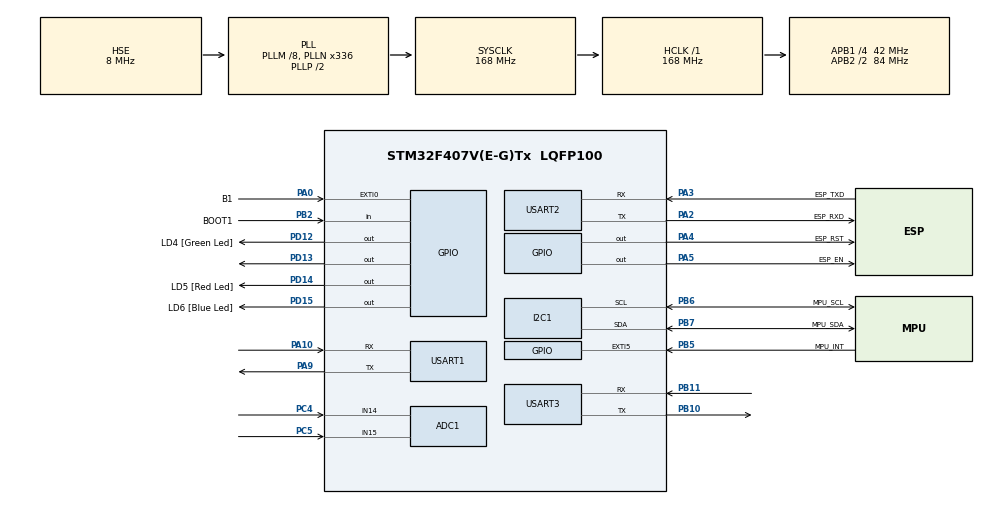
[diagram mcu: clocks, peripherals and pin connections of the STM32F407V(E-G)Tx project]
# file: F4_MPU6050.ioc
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ADC1.Channel-4\#ChannelRegularConversion=ADC_CHANNEL_14
ADC1.Channel-5\#ChannelRegularConversion=ADC_CHANNEL_15
ADC1.DMAContinuousRequests=ENABLE
ADC1.EOCSelection=ADC_EOC_SEQ_CONV
ADC1.ExternalTrigConv=ADC_EXTERNALTRIGCONV_T3_TRGO
ADC1.NbrOfConversion=2
ADC1.NbrOfConversionFlag=1
ADC1.Rank-4\#ChannelRegularConversion=1
ADC1.Rank-5\#ChannelRegularConversion=2
ADC1.SamplingTime-4\#ChannelRegularConversion=ADC_SAMPLETIME_15CYCLES
ADC1.SamplingTime-5\#ChannelRegularConversion=ADC_SAMPLETIME_15CYCLES
ADC1.ScanConvMode=ENABLE
ADC1.master=1
Dma.ADC1.4.Direction=DMA_PERIPH_TO_MEMORY
Dma.ADC1.4.FIFOMode=DMA_FIFOMODE_ENABLE
Dma.ADC1.4.FIFOThreshold=DMA_FIFO_THRESHOLD_FULL
Dma.ADC1.4.Instance=DMA2_Stream0
Dma.ADC1.4.MemBurst=DMA_MBURST_SINGLE
Dma.ADC1.4.MemDataAlignment=DMA_MDATAALIGN_WORD
Dma.ADC1.4.MemInc=DMA_MINC_ENABLE
Dma.ADC1.4.Mode=DMA_NORMAL
Dma.ADC1.4.PeriphBurst=DMA_PBURST_SINGLE
Dma.ADC1.4.PeriphDataAlignment=DMA_PDATAALIGN_WORD
Dma.ADC1.4.PeriphInc=DMA_PINC_DISABLE
Dma.ADC1.4.Priority=DMA_PRIORITY_HIGH
Dma.Request0=USART2_RX
Dma.Request1=USART2_TX
Dma.Request2=USART3_RX
Dma.Request3=USART3_TX
Dma.Request4=ADC1
Dma.USART2_RX.0.Direction=DMA_PERIPH_TO_MEMORY
Dma.USART2_RX.0.FIFOMode=DMA_FIFOMODE_DISABLE
Dma.USART2_RX.0.Instance=DMA1_Stream5
Dma.USART2_RX.0.MemDataAlignment=DMA_MDATAALIGN_BYTE
Dma.USART2_RX.0.MemInc=DMA_MINC_ENABLE
Dma.USART2_RX.0.Mode=DMA_NORMAL
Dma.USART2_RX.0.PeriphDataAlignment=DMA_PDATAALIGN_BYTE
Dma.USART2_RX.0.PeriphInc=DMA_PINC_DISABLE
Dma.USART2_RX.0.Priority=DMA_PRIORITY_LOW
Dma.USART2_TX.1.Direction=DMA_MEMORY_TO_PERIPH
Dma.USART2_TX.1.FIFOMode=DMA_FIFOMODE_DISABLE
Dma.USART2_TX.1.Instance=DMA1_Stream6
Dma.USART2_TX.1.MemDataAlignment=DMA_MDATAALIGN_BYTE
Dma.USART2_TX.1.MemInc=DMA_MINC_ENABLE
Dma.USART2_TX.1.Mode=DMA_NORMAL
Dma.USART2_TX.1.PeriphDataAlignment=DMA_PDATAALIGN_BYTE
Dma.USART2_TX.1.PeriphInc=DMA_PINC_DISABLE
Dma.USART2_TX.1.Priority=DMA_PRIORITY_LOW
Dma.USART3_RX.2.Direction=DMA_PERIPH_TO_MEMORY
Dma.USART3_RX.2.FIFOMode=DMA_FIFOMODE_DISABLE
Dma.USART3_RX.2.Instance=DMA1_Stream1
Dma.USART3_RX.2.MemDataAlignment=DMA_MDATAALIGN_BYTE
Dma.USART3_RX.2.MemInc=DMA_MINC_ENABLE
Dma.USART3_RX.2.Mode=DMA_NORMAL
Dma.USART3_RX.2.PeriphDataAlignment=DMA_PDATAALIGN_BYTE
Dma.USART3_RX.2.PeriphInc=DMA_PINC_DISABLE
Dma.USART3_RX.2.Priority=DMA_PRIORITY_LOW
Dma.USART3_TX.3.Direction=DMA_MEMORY_TO_PERIPH
Dma.USART3_TX.3.FIFOMode=DMA_FIFOMODE_DISABLE
Dma.USART3_TX.3.Instance=DMA1_Stream3
Dma.USART3_TX.3.MemDataAlignment=DMA_MDATAALIGN_BYTE
Dma.USART3_TX.3.MemInc=DMA_MINC_ENABLE
Dma.USART3_TX.3.Mode=DMA_NORMAL
Dma.USART3_TX.3.PeriphDataAlignment=DMA_PDATAALIGN_BYTE
Dma.USART3_TX.3.PeriphInc=DMA_PINC_DISABLE
Dma.USART3_TX.3.Priority=DMA_PRIORITY_LOW
Mcu.Family=STM32F4
Mcu.Name=STM32F407V(E-G)Tx
Mcu.Package=LQFP100
NVIC.DMA1_Stream1_IRQn=true\:0\:0\:false\:false\:true\:false\:true
NVIC.DMA1_Stream3_IRQn=true\:0\:0\:false\:false\:true\:false\:true
NVIC.DMA1_Stream5_IRQn=true\:0\:0\:false\:false\:true\:false\:true
NVIC.DMA1_Stream6_IRQn=true\:0\:0\:false\:false\:true\:false\:true
NVIC.DMA2_Stream0_IRQn=true\:0\:0\:false\:false\:true\:false\:true
NVIC.EXTI0_IRQn=true\:0\:0\:false\:false\:true\:true\:true
NVIC.EXTI9_5_IRQn=true\:0\:0\:false\:false\:true\:true\:true
NVIC.PriorityGroup=NVIC_PRIORITYGROUP_4
NVIC.TIM3_IRQn=true\:1\:0\:true\:false\:true\:true\:true
NVIC.TIM7_IRQn=true\:2\:0\:true\:false\:true\:true\:true
NVIC.USART2_IRQn=true\:0\:0\:false\:false\:true\:true\:true
NVIC.USART3_IRQn=true\:0\:0\:false\:false\:true\:true\:true
PA0-WKUP.GPIO_Label=B1
PA0-WKUP.Signal=GPXTI0
PA10.Mode=Asynchronous
PA10.Signal=USART1_RX
PA13.GPIO_Label=SWDIO
PA13.Mode=Serial_Wire
PA13.Signal=SYS_JTMS-SWDIO
PA14.GPIO_Label=SWCLK
PA14.Mode=Serial_Wire
PA14.Signal=SYS_JTCK-SWCLK
PA2.GPIO_Label=ESP_RXD
PA2.Mode=Asynchronous
PA2.Signal=USART2_TX
PA3.GPIO_Label=ESP_TXD
PA3.Mode=Asynchronous
PA3.Signal=USART2_RX
PA4.GPIO_Label=ESP_RST
PA4.Signal=GPIO_Output
PA5.GPIO_Label=ESP_EN
PA5.Signal=GPIO_Output
PA9.Mode=Asynchronous
PA9.Signal=USART1_TX
PB10.Mode=Asynchronous
PB10.Signal=USART3_TX
PB11.Mode=Asynchronous
PB11.Signal=USART3_RX
PB2.GPIO_Label=BOOT1
PB2.GPIO_Mode=GPIO_MODE_INPUT
PB2.GPIO_PuPd=GPIO_NOPULL
PB2.Signal=GPIO_Input
PB5.GPIO_Label=MPU_INT
PB5.Signal=GPXTI5
PB6.GPIO_Label=MPU_SCL
PB6.Mode=I2C
PB6.Signal=I2C1_SCL
PB7.GPIO_Label=MPU_SDA
PB7.Mode=I2C
PB7.Signal=I2C1_SDA
PC14-OSC32_IN.GPIO_Label=PC14-OSC32_IN
PC14-OSC32_IN.Mode=LSE-External-Oscillator
PC14-OSC32_IN.Signal=RCC_OSC32_IN
PC15-OSC32_OUT.GPIO_Label=PC15-OSC32_OUT
PC15-OSC32_OUT.Mode=LSE-External-Oscillator
PC15-OSC32_OUT.Signal=RCC_OSC32_OUT
PC4.Signal=ADCx_IN14
PC5.Signal=ADCx_IN15
PD12.GPIO_Label=LD4 [Green Led]
PD12.GPIO_PuPd=GPIO_NOPULL
PD12.GPIO_Speed=GPIO_SPEED_FREQ_LOW
PD12.Signal=GPIO_Output
PD13.Signal=GPIO_Output
PD14.GPIO_Label=LD5 [Red Led]
PD14.GPIO_PuPd=GPIO_NOPULL
PD14.GPIO_Speed=GPIO_SPEED_FREQ_LOW
PD14.Signal=GPIO_Output
PD15.GPIO_Label=LD6 [Blue Led]
PD15.GPIO_PuPd=GPIO_NOPULL
PD15.GPIO_Speed=GPIO_SPEED_FREQ_LOW
PD15.Signal=GPIO_Output
PH0-OSC_IN.GPIO_Label=PH0-OSC_IN
PH0-OSC_IN.Mode=HSE-External-Oscillator
PH0-OSC_IN.Signal=RCC_OSC_IN
PH1-OSC_OUT.GPIO_Label=PH1-OSC_OUT
PH1-OSC_OUT.Mode=HSE-External-Oscillator
PH1-OSC_OUT.Signal=RCC_OSC_OUT
ProjectManager.HeapSize=0x200
ProjectManager.StackSize=0x400
ProjectManager.TargetToolchain=STM32CubeIDE
RCC.48MHZClocksFreq_Value=48000000
RCC.AHBFreq_Value=168000000
RCC.APB1CLKDivider=RCC_HCLK_DIV4
RCC.APB1Freq_Value=42000000
RCC.APB1TimFreq_Value=84000000
RCC.APB2CLKDivider=RCC_HCLK_DIV2
RCC.APB2Freq_Value=84000000
RCC.APB2TimFreq_Value=168000000
RCC.CortexFreq_Value=168000000
RCC.HCLKFreq_Value=168000000
RCC.HSE_VALUE=8000000
RCC.HSI_VALUE=16000000
RCC.PLLM=8
RCC.PLLN=336
RCC.PLLQ=7
RCC.PLLSourceVirtual=RCC_PLLSOURCE_HSE
RCC.SYSCLKFreq_VALUE=168000000
RCC.SYSCLKSource=RCC_SYSCLKSOURCE_PLLCLK
RCC.VCOOutputFreq_Value=336000000
SH.ADCx_IN14.0=ADC1_IN14,IN14
SH.ADCx_IN15.0=ADC1_IN15,IN15
TIM3.AutoReloadPreload=TIM_AUTORELOAD_PRELOAD_ENABLE
TIM3.Period=4199
TIM3.Prescaler=0
TIM3.TIM_MasterOutputTrigger=TIM_TRGO_UPDATE
TIM7.AutoReloadPreload=TIM_AUTORELOAD_PRELOAD_ENABLE
TIM7.Period=19999
TIM7.Prescaler=839
TIM7.TIM_MasterOutputTrigger=TIM_TRGO_RESET
USART1.VirtualMode=VM_ASYNC
USART2.VirtualMode=VM_ASYNC
USART3.VirtualMode=VM_ASYNC
VP_TIM3_VS_ClockSourceINT.Mode=Internal
VP_TIM7_VS_ClockSourceINT.Mode=Enable_Timer
board=STM32F407G-DISC1

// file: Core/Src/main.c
/* USER CODE BEGIN Header */
/**
  ******************************************************************************
  * @file           : main.c
  * @brief          : Main program body
  ******************************************************************************
  * @attention
  *
  * <h2><center>&copy; Copyright (c) 2021 STMicroelectronics.
  * All rights reserved.</center></h2>
  *
  * This software component is licensed by ST under Ultimate Liberty license
  * SLA0044, the "License"; You may not use this file except in compliance with
  * the License. You may obtain a copy of the License at:
  *                             www.st.com/SLA0044
  *
  ******************************************************************************
  */
/* USER CODE END Header */
#include "main.h"
#include "adc.h"
#include "dma.h"
#include "i2c.h"
#include "tim.h"
#include "usart.h"
#include "gpio.h"

/* USER CODE BEGIN Includes */
#include "esp8266_at.h"
#include "my_uart.h"
#include "mpu6050.h"
#include "HMI.h"
#include "my_adc.h"
/* USER CODE END Includes */

/* USER CODE BEGIN PV */

/*系统状态机*/
System_Status_TypeDef sysStatus;

/* USER CODE END PV */

void SystemClock_Config(void);

int main(void)
{

  /* MCU Configuration--------------------------------------------------------*/

  /* Reset of all peripherals, Initializes the Flash interface and the Systick. */
  HAL_Init();

  /* Configure the system clock */
  SystemClock_Config();

  /* Initialize all configured peripherals */
  MX_GPIO_Init();
  MX_DMA_Init();
  MX_I2C1_Init();
  MX_USART2_UART_Init();
  MX_USART3_UART_Init();
  MX_USART1_UART_Init();
  MX_ADC1_Init();
  MX_TIM3_Init();
  MX_TIM7_Init();
  /* USER CODE BEGIN 2 */
  SystemStartTask();

  /* USER CODE END 2 */

  /* Infinite loop */
  /* USER CODE BEGIN WHILE */
  while (1)
  {

	  switch(sysStatus){
	  case MAIN_MENU	:	MainMenuTask();		break;

	  case MPU6050_MODE	:	MPU6050Task();		break;

	  case DSO_MODE		:	DSOTask();			break;

	  default	:	break;

	  }

    /* USER CODE END WHILE */

  }
}

void SystemClock_Config(void)
{
  RCC_OscInitTypeDef RCC_OscInitStruct = {0};
  RCC_ClkInitTypeDef RCC_ClkInitStruct = {0};

  /** Configure the main internal regulator output voltage
  */
  __HAL_RCC_PWR_CLK_ENABLE();
  __HAL_PWR_VOLTAGESCALING_CONFIG(PWR_REGULATOR_VOLTAGE_SCALE1);
  /** Initializes the RCC Oscillators according to the specified parameters
  * in the RCC_OscInitTypeDef structure.
  */
  RCC_OscInitStruct.OscillatorType = RCC_OSCILLATORTYPE_HSE;
  RCC_OscInitStruct.HSEState = RCC_HSE_ON;
  RCC_OscInitStruct.PLL.PLLState = RCC_PLL_ON;
  RCC_OscInitStruct.PLL.PLLSource = RCC_PLLSOURCE_HSE;
  RCC_OscInitStruct.PLL.PLLM = 8;
  RCC_OscInitStruct.PLL.PLLN = 336;
  RCC_OscInitStruct.PLL.PLLP = RCC_PLLP_DIV2;
  RCC_OscInitStruct.PLL.PLLQ = 7;
  if (HAL_RCC_OscConfig(&RCC_OscInitStruct) != HAL_OK)
  {
    Error_Handler();
  }
  /** Initializes the CPU, AHB and APB buses clocks
  */
  RCC_ClkInitStruct.ClockType = RCC_CLOCKTYPE_HCLK|RCC_CLOCKTYPE_SYSCLK
                              |RCC_CLOCKTYPE_PCLK1|RCC_CLOCKTYPE_PCLK2;
  RCC_ClkInitStruct.SYSCLKSource = RCC_SYSCLKSOURCE_PLLCLK;
  RCC_ClkInitStruct.AHBCLKDivider = RCC_SYSCLK_DIV1;
  RCC_ClkInitStruct.APB1CLKDivider = RCC_HCLK_DIV4;
  RCC_ClkInitStruct.APB2CLKDivider = RCC_HCLK_DIV2;

  if (HAL_RCC_ClockConfig(&RCC_ClkInitStruct, FLASH_LATENCY_5) != HAL_OK)
  {
    Error_Handler();
  }
}

/* USER CODE BEGIN 4 */
//void HAL_ADC_ConvCpltCallback(ADC_HandleTypeDef* hadc){
//	if(hadc == &hadc1){
//		printf("1:%d, 2:%d\r\n",ADC_Value[0], ADC_Value[1]);
//	}
//}
/* USER CODE END 4 */

void Error_Handler(void)
{
  __disable_irq();
  while (1)
  {
  }
}

/************************ (C) COPYRIGHT STMicroelectronics *****END OF FILE****/
